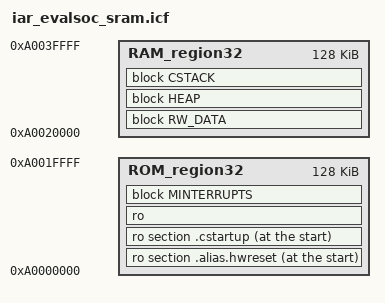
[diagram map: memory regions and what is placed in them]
//////////////////////////////////////////////////////////////////////
// RISC-V ilink configuration file
// for the Nuclei Evaluation SoC SRAM Linker File
//

define exported symbol _link_file_version_2 = 1;

define memory mem with size = 4G;

define region ROM_region32 = mem:[from 0xA0000000 to 0xA001FFFF];
define region RAM_region32 = mem:[from 0xA0020000 to 0xA003FFFF];

initialize by copy { rw };
do not initialize  { section *.noinit };
keep symbol __iar_cstart_init_gp; // defined in cstartup.s

define block CSTACK with alignment = 16, size = CSTACK_SIZE { };
define block HEAP   with alignment = 16, size = HEAP_SIZE   { };

define block MINTERRUPTS with maximum size =  64k { ro section .mtext };

define block RW_DATA with static base GPREL { rw data };
keep { ro section .alias.hwreset };

"CSTARTUP32" : place at start of ROM_region32 { ro section .alias.hwreset,
                                                ro section .cstartup };

"ROM32":place in ROM_region32        { ro,
                                       block MINTERRUPTS };

"RAM32":place in RAM_region32        { block RW_DATA,
                                       block HEAP,
                                       block CSTACK };
